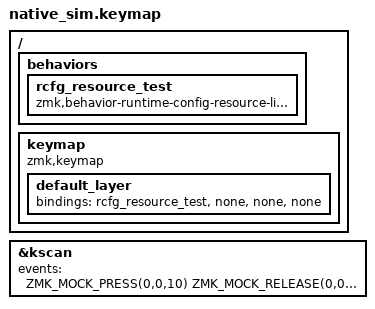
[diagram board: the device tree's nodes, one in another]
#include <dt-bindings/zmk/keys.h>
#include <behaviors.dtsi>
#include <dt-bindings/zmk/kscan_mock.h>

/ {
    behaviors {
        rcfg_resource_test: rcfg_resource_test {
            compatible = "zmk,behavior-runtime-config-resource-limit-test";
            #binding-cells = <0>;
        };
    };

    keymap {
        compatible = "zmk,keymap";

        default_layer {
            bindings = <&rcfg_resource_test &none &none &none>;
        };
    };
};

&kscan {
    events = <
        ZMK_MOCK_PRESS(0,0,10)
        ZMK_MOCK_RELEASE(0,0,10)
    >;
};
